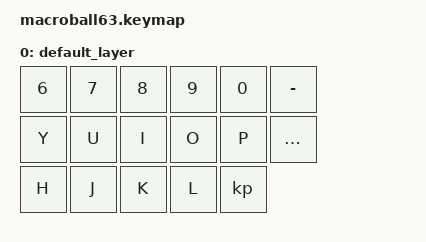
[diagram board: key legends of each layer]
#include <behaviors.dtsi>
#include <dt-bindings/zmk/bt.h>
#include <dt-bindings/zmk/keys.h>
#include <dt-bindings/zmk/pointing.h>

&mt {
    flavor = "balanced";
    quick-tap-ms = <0>;
};

&trackball {
    automouse-layer = <4>;
    scroll-layers = <5>;
};

/ {
    combos {
        compatible = "zmk,combos";

        tab {
            bindings = <&kp TAB>;
            key-positions = <11 12>;
        };

        shift_tab {
            bindings = <&kp LS(TAB)>;
            key-positions = <12 13>;
        };

        muhennkann {
            bindings = <&to_layer_0 INT_MUHENKAN>;
            key-positions = <11 10>;
        };

        double_quotation {
            bindings = <&kp DOUBLE_QUOTES>;
            key-positions = <20 21>;
        };

        eq {
            bindings = <&kp EQUAL>;
            key-positions = <24 25>;
        };
    };

    macros {
        to_layer_0: to_layer_0 {
            compatible = "zmk,behavior-macro-one-param";
            #binding-cells = <1>;
            bindings = <&to 0 &macro_param_1to1 &kp MACRO_PLACEHOLDER>;
            label = "TO_LAYER_0";
        };
    };

    behaviors {
        lt_to_layer_0: lt_to_layer_0 {
            compatible = "zmk,behavior-hold-tap";
            label = "LAYER_TAP_TO_0";
            bindings = <&mo>, <&to_layer_0>;

            #binding-cells = <2>;
            tapping-term-ms = <200>;
        };
    };

    keymap {
        compatible = "zmk,keymap";

        default_layer {
            bindings = <
&kp 6 &kp 7 &kp 8 &kp 9 &kp 0 &kp -
&kp Y &kp U &kp I &kp O &kp P &kp ＝
&kp H &kp J &kp K &kp L &kp ; &kp '
&kp N &kp M &kp , &kp . &kp / &kp A
&kp Y &kp Z &kp NUMBER_1 &kp NUMBER_2 &kp NUMBER_3 &kp NUMBER_4
            >;
        };
    };
};
